# ATSAM4E16CB register map
Vendor: Atmel; Series: SAM4E; File version: 0
CPU: CM4 r0p1, selectable endian, MPU, FPU, 4 interrupt priority bits
Registers are 32-bit, read-write, reset 0x0 unless marked. A register's access mark holds for its fields unless they carry their own. Offsets are from the block's base; [hi:lo] are bit positions; {n}, {i} and the like mark numbered series.

## SMC — Static Memory Controller
Base 0x40060000; register names take the prefix SMC_
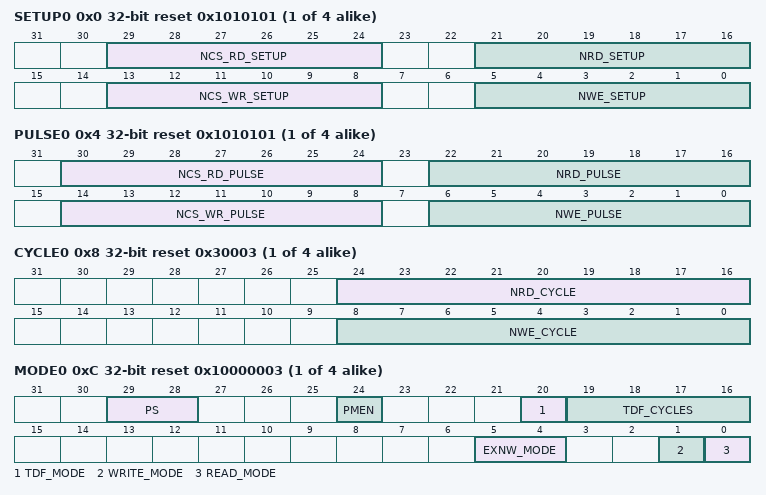
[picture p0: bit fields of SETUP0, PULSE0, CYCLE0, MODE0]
{0x0+0x10*i} SETUP{i} reset 0x1010101 (i=0..3) — SMC Setup Register (CS_number = {i})
  [29:24] NCS_RD_SETUP — NCS Setup Length in READ Access
  [21:16] NRD_SETUP — NRD Setup Length
  [13:8] NCS_WR_SETUP — NCS Setup Length in WRITE Access
  [5:0] NWE_SETUP — NWE Setup Length
{0x4+0x10*i} PULSE{i} reset 0x1010101 (i=0..3) — SMC Pulse Register (CS_number = {i})
  [30:24] NCS_RD_PULSE — NCS Pulse Length in READ Access
  [22:16] NRD_PULSE — NRD Pulse Length
  [14:8] NCS_WR_PULSE — NCS Pulse Length in WRITE Access
  [6:0] NWE_PULSE — NWE Pulse Length
{0x8+0x10*i} CYCLE{i} reset 0x30003 (i=0..3) — SMC Cycle Register (CS_number = {i})
  [24:16] NRD_CYCLE — Total Read Cycle Length
  [8:0] NWE_CYCLE — Total Write Cycle Length
{0xC+0x10*i} MODE{i} reset 0x10000003 (i=0..3) — SMC Mode Register (CS_number = {i})
  [29:28] PS — Page Size
    0=4_BYTE (4-byte page); 1=8_BYTE (8-byte page); 2=16_BYTE (16-byte page); 3=32_BYTE (32-byte page)
  [24] PMEN — Page Mode Enabled
  [20] TDF_MODE — TDF Optimization
  [19:16] TDF_CYCLES — Data Float Time
  [5:4] EXNW_MODE — NWAIT Mode
    0=DISABLED; 2=FROZEN (Frozen Mode); 3=READY (Ready Mode)
  [1] WRITE_MODE
  [0] READ_MODE
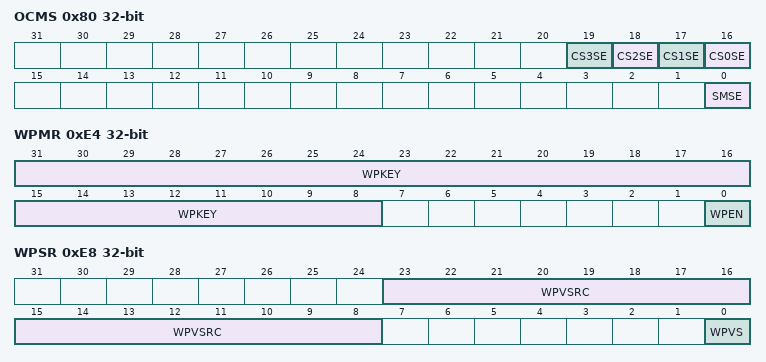
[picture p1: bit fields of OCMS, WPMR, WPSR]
0x80 OCMS — SMC OCMS MODE Register
  [n+16] CS{n}SE (n=0..3) — Chip Select (x = 0 to 3) Scrambling Enable
  [0] SMSE — Static Memory Controller Scrambling Enable
0x84 KEY1 wo — SMC OCMS KEY1 Register
  [31:0] KEY1 — Off Chip Memory Scrambling (OCMS) Key Part 1
0x88 KEY2 wo — SMC OCMS KEY2 Register
  [31:0] KEY2 — Off Chip Memory Scrambling (OCMS) Key Part 2
0xE4 WPMR — SMC Write Protect Mode Register
  [31:8] WPKEY — Write Protect KEY
  [0] WPEN — Write Protect Enable
0xE8 WPSR ro — SMC Write Protect Status Register
  [23:8] WPVSRC — Write Protect Violation Source
  [0] WPVS — Write Protect Enable

## ACC — Analog Comparator Controller
Base 0x400BC000; register names take the prefix ACC_
0x00 CR wo reset not defined — Control Register
  [0] SWRST — Software Reset
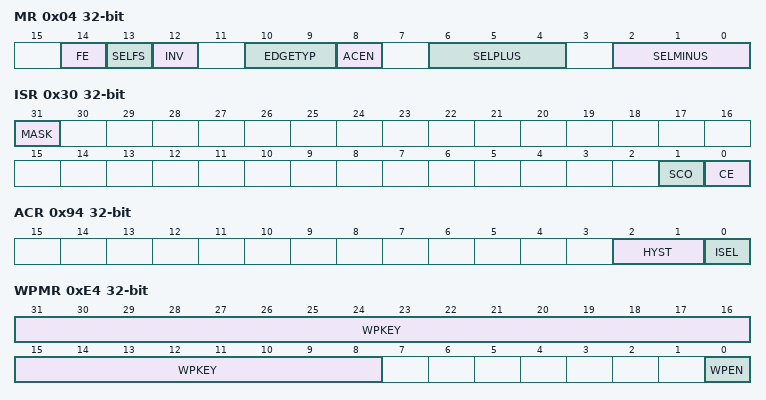
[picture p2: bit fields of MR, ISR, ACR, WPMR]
0x04 MR — Mode Register
  [14] FE — Fault Enable
    0=DIS (The FAULT output is tied to 0.); 1=EN (The FAULT output is driven by the signal defined by SELFS.)
  [13] SELFS — Selection Of Fault Source
    0=CF (The CF flag is used to drive the FAULT output.); 1=OUTPUT (The output of the analog comparator flag is used to drive the FAULT output.)
  [12] INV — Invert Comparator Output
    0=DIS (Analog comparator output is directly processed.); 1=EN (Analog comparator output is inverted prior to being processed.)
  [10:9] EDGETYP — Edge Type
    0=RISING (Only rising edge of comparator output); 1=FALLING (Falling edge of comparator output); 2=ANY (Any edge of comparator output)
  [8] ACEN — Analog Comparator Enable
    0=DIS (Analog comparator disabled.); 1=EN (Analog comparator enabled.)
  [6:4] SELPLUS — Selection For Plus Comparator Input
    {v}=AD{v} (Select AD{v}) (v=0..7)
  [2:0] SELMINUS — Selection for Minus Comparator Input
    0=TS (Select TS); 1=ADVREF (Select ADVREF); 2=DAC0 (Select DAC0); 3=DAC1 (Select DAC1); {v}=AD{v-4} (Select AD{v-4}) (v=4..7)
0x24 IER wo reset not defined — Interrupt Enable Register
  [0] CE — Comparison Edge
0x28 IDR wo reset not defined — Interrupt Disable Register
  [0] CE — Comparison Edge
0x2C IMR ro — Interrupt Mask Register
  [0] CE — Comparison Edge
0x30 ISR ro — Interrupt Status Register
  [31] MASK — Flag Mask
  [1] SCO — Synchronized Comparator Output
  [0] CE — Comparison Edge
0x94 ACR — Analog Control Register
  [2:1] HYST — Hysteresis Selection
  [0] ISEL — Current Selection
    0=LOPW (Low-power option.); 1=HISP (High-speed option.)
0xE4 WPMR — Write Protection Mode Register
  [31:8] WPKEY — Write Protection Key
    0x414343=PASSWD (Writing any other value in this field aborts the write operation of the WPEN bit.Always reads as 0.)
  [0] WPEN — Write Protection Enable
0xE8 WPSR ro — Write Protection Status Register
  [0] WPVS — Write Protection Violation Status
